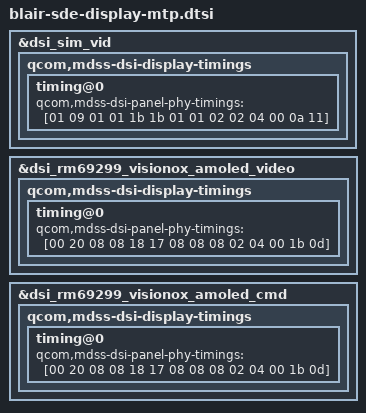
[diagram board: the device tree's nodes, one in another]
/* Should extend holi-sde-display-mtp-pm6125.dtsi */

&dsi_sim_vid {
	qcom,mdss-dsi-display-timings {
		timing@0 {
			qcom,mdss-dsi-panel-phy-timings = [01 09 01 01 1b 1b 01
							01 02 02 04 00 0a 11];
		};
	};
};

&dsi_rm69299_visionox_amoled_video {
	qcom,mdss-dsi-display-timings {
		timing@0 {
			qcom,mdss-dsi-panel-phy-timings = [00 20 08 08 18 17 08
							08 08 02 04 00 1b 0d];
		};
	};
};

&dsi_rm69299_visionox_amoled_cmd {
	qcom,mdss-dsi-display-timings {
		timing@0 {
			qcom,mdss-dsi-panel-phy-timings = [00 20 08 08 18 17 08
							08 08 02 04 00 1b 0d];
		};
	};
};
